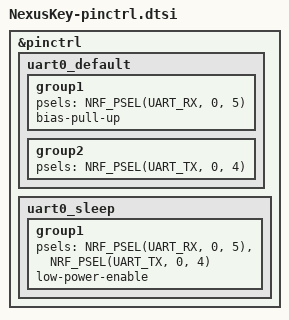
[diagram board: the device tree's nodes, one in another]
/*
 * Copyright (c) 2022 The ZMK Contributors
 * SPDX-License-Identifier: MIT
 */

&pinctrl {
    uart0_default: uart0_default {
        group1 {
            psels = <NRF_PSEL(UART_RX, 0, 5)>;
            bias-pull-up;
        };
        group2 {
            psels = <NRF_PSEL(UART_TX, 0, 4)>;
        };
    };

    uart0_sleep: uart0_sleep {
        group1 {
            psels = <NRF_PSEL(UART_RX, 0, 5)>,
                <NRF_PSEL(UART_TX, 0, 4)>;
            low-power-enable;
        };
    };
};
